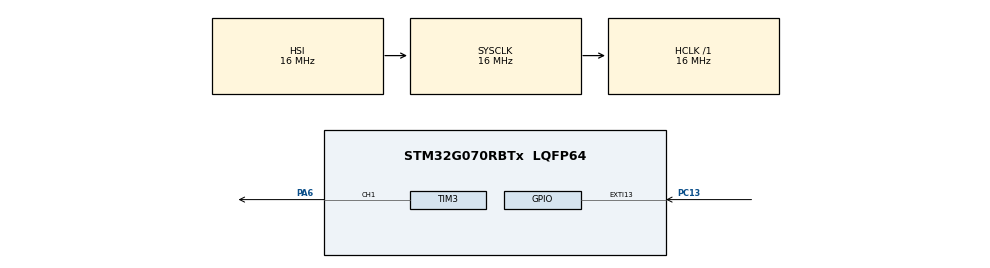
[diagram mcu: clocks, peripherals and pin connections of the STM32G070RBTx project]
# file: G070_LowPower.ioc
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Mcu.Family=STM32G0
Mcu.Name=STM32G070RBTx
Mcu.Package=LQFP64
NVIC.EXTI4_15_IRQn=true\:0\:0\:true\:false\:true\:true\:true\:true
NVIC.TIM6_IRQn=true\:0\:0\:false\:false\:true\:true\:true\:true
PA13.Mode=Serial_Wire
PA13.Signal=SYS_SWDIO
PA14-BOOT0.Mode=Serial_Wire
PA14-BOOT0.Signal=SYS_SWCLK
PA6.Signal=S_TIM3_CH1
PC13.GPIO_ModeDefaultEXTI=GPIO_MODE_IT_RISING
PC13.Signal=GPXTI13
ProjectManager.HeapSize=0x200
ProjectManager.StackSize=0x400
ProjectManager.TargetToolchain=STM32CubeIDE
RCC.ADCFreq_Value=16000000
RCC.AHBFreq_Value=16000000
RCC.CortexFreq_Value=16000000
RCC.EXTERNAL_CLOCK_VALUE=48000
RCC.HCLKFreq_Value=16000000
RCC.HSE_VALUE=8000000
RCC.HSI_VALUE=16000000
RCC.LSE_VALUE=32768
RCC.SYSCLKFreq_VALUE=16000000
RCC.VCOOutputFreq_Value=128000000
SH.S_TIM3_CH1.0=TIM3_CH1,PWM Generation1 CH1
TIM3.AutoReloadPreload=TIM_AUTORELOAD_PRELOAD_ENABLE
TIM3.Channel-PWM\ Generation1\ CH1=TIM_CHANNEL_1
TIM3.ClockDivision=TIM_CLOCKDIVISION_DIV1
TIM3.Period=499
TIM3.Prescaler=31
TIM3.Pulse-PWM\ Generation1\ CH1=249
TIM6.Period=199
TIM6.Prescaler=31
VP_TIM3_VS_ClockSourceINT.Mode=Internal
VP_TIM6_VS_ClockSourceINT.Mode=Enable_Timer
board=custom

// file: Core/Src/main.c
/* USER CODE BEGIN Header */
/**
  ******************************************************************************
  * @file           : main.c
  * @brief          : Main program body
  ******************************************************************************
  * @attention
  *
  * Copyright (c) 2025 STMicroelectronics.
  * All rights reserved.
  *
  * This software is licensed under terms that can be found in the LICENSE file
  * in the root directory of this software component.
  * If no LICENSE file comes with this software, it is provided AS-IS.
  *
  ******************************************************************************
  */
/* USER CODE END Header */
#include "main.h"

TIM_HandleTypeDef htim3;
TIM_HandleTypeDef htim6;

/* USER CODE BEGIN PV */
uint8_t mode = 0;
/* USER CODE END PV */

void SystemClock_Config(void);
static void MX_GPIO_Init(void);
static void MX_TIM3_Init(void);
static void MX_TIM6_Init(void);

/* USER CODE BEGIN 0 */

void HAL_TIM_PeriodElapsedCallback(TIM_HandleTypeDef *htim)
{
	if(htim->Instance == TIM6)
	{
		HAL_TIM_Base_Stop(&htim6);
	    if(HAL_GPIO_ReadPin(GPIOC, GPIO_PIN_13)== GPIO_PIN_SET)
		{

			switch(mode)
			{
			case 0:
				HAL_TIM_PWM_Start(&htim3, TIM_CHANNEL_1);
				mode= 1;
				break;
			case 1:
				__HAL_TIM_SET_AUTORELOAD(&htim3, 999);
				TIM3->EGR |= TIM_EGR_UG;  // Triggering UPDATE EVENT, Gives clear feedback on button press
				mode =2;
				break;
			case 2:
				__HAL_TIM_SET_AUTORELOAD(&htim3, 1999);
				TIM3->EGR |= TIM_EGR_UG;  // Triggering UPDATE EVENT, Gives clear feedback on button press
				mode = 3;
				break;
			case 3:
				__HAL_TIM_SET_AUTORELOAD(&htim3, 499);
				TIM3->EGR |= TIM_EGR_UG;  // Triggering UPDATE EVENT, Gives clear feedback on button press
				HAL_TIM_PWM_Stop(&htim3, TIM_CHANNEL_1);
				mode =0;

			}
		}
	}
}

void HAL_GPIO_EXTI_Rising_Callback(uint16_t GPIO_Pin)
{
	if(GPIO_Pin == GPIO_PIN_13)
	{
		//Start TIM 6 for Debouncing
		HAL_TIM_Base_Start_IT(&htim6);
	}
}

void LOW_POWER_CLK_CONFIG(void)
{
  RCC_OscInitTypeDef RCC_LSI_init_Struct = {0};
  RCC_OscInitTypeDef RCC_HSI_delete_Struct = {0};
  RCC_ClkInitTypeDef RCC_ClkInitStruct = {0};

  HAL_PWREx_ControlVoltageScaling(PWR_REGULATOR_VOLTAGE_SCALE2);

   // Configure the LSI oscillator
  RCC_LSI_init_Struct.OscillatorType = RCC_OSCILLATORTYPE_LSI;
  RCC_LSI_init_Struct.LSIState = RCC_LSI_ON;  // Enable LSI
  RCC_LSI_init_Struct.PLL.PLLState = RCC_PLL_NONE;  // No PLL configuration

  if (HAL_RCC_OscConfig(&RCC_LSI_init_Struct) != HAL_OK)
  {
	  Error_Handler();
  }

  // Wait until LSI is ready
  while (!(READ_BIT(RCC->CSR, RCC_CSR_LSIRDY)))
  {
      __NOP();  // Wait for LSI to stabilize
  }

  //Configue LSI as SYSCLK
  RCC_ClkInitStruct.ClockType = RCC_CLOCKTYPE_SYSCLK;
  RCC_ClkInitStruct.SYSCLKSource = RCC_SYSCLKSOURCE_LSI;
  RCC_ClkInitStruct.AHBCLKDivider = RCC_SYSCLK_DIV1;
  RCC_ClkInitStruct.APB1CLKDivider = RCC_HCLK_DIV1;
  HAL_RCC_ClockConfig(&RCC_ClkInitStruct, FLASH_LATENCY_0);

  //Disabling HSI
  RCC_HSI_delete_Struct.OscillatorType = RCC_OSCILLATORTYPE_NONE;
  RCC_HSI_delete_Struct.HSIState = RCC_HSI_OFF;
  HAL_RCC_OscConfig(&RCC_HSI_delete_Struct);

  // Wait until HSI is off
  while (READ_BIT(RCC->CR, RCC_CR_HSIRDY))
  {
      __NOP();
  }

  // MAKE sure PLL is disabled
  RCC->CR &= ~RCC_CR_PLLON;  // Disable PLL
  while((RCC->CR & RCC_CR_PLLRDY) != 0);  // Wait for PLL to stop

}
/* USER CODE END 0 */

int main(void)
{

  /* MCU Configuration--------------------------------------------------------*/

  /* Reset of all peripherals, Initializes the Flash interface and the Systick. */
  HAL_Init();

  /* Configure the system clock */
  SystemClock_Config();

  /* Initialize all configured peripherals */
  MX_GPIO_Init();
  MX_TIM3_Init();
  MX_TIM6_Init();
  /* USER CODE BEGIN 2 */
  __HAL_RCC_PWR_CLK_ENABLE();

  LOW_POWER_CLK_CONFIG();

  // Suspend the Systick Interrupt
  HAL_SuspendTick();

  //Enable the Sleep on Exit bit to make sure the processor goes back to SLEEP
  //after an interrupt has been serviced
  HAL_PWR_EnableSleepOnExit();

  /*
   * Enter Sleep mode with the PWR_LOWPOWERREGULATOR_ON to make sure it
   * runs on Low-Power Run and Low-Power Sleep mode.
   * We also make sure to enable PWR_SLEEPENTRY_WFI so that the cpu wakes
   * up from Low-Power Sleep Mode when the button EXTI interrupt is triggered
   */
  HAL_PWR_EnterSLEEPMode(PWR_LOWPOWERREGULATOR_ON, PWR_SLEEPENTRY_WFI);

  /* USER CODE END 2 */

  /* Infinite loop */
  while (1)
  {

  }
}

void SystemClock_Config(void)
{
  RCC_OscInitTypeDef RCC_OscInitStruct = {0};
  RCC_ClkInitTypeDef RCC_ClkInitStruct = {0};

  /** Configure the main internal regulator output voltage
  */
  HAL_PWREx_ControlVoltageScaling(PWR_REGULATOR_VOLTAGE_SCALE1);

  /** Initializes the RCC Oscillators according to the specified parameters
  * in the RCC_OscInitTypeDef structure.
  */
  RCC_OscInitStruct.OscillatorType = RCC_OSCILLATORTYPE_HSI;
  RCC_OscInitStruct.HSIState = RCC_HSI_ON;
  RCC_OscInitStruct.HSIDiv = RCC_HSI_DIV1;
  RCC_OscInitStruct.HSICalibrationValue = RCC_HSICALIBRATION_DEFAULT;
  RCC_OscInitStruct.PLL.PLLState = RCC_PLL_NONE;
  if (HAL_RCC_OscConfig(&RCC_OscInitStruct) != HAL_OK)
  {
    Error_Handler();
  }

  /** Initializes the CPU, AHB and APB buses clocks
  */
  RCC_ClkInitStruct.ClockType = RCC_CLOCKTYPE_HCLK|RCC_CLOCKTYPE_SYSCLK
                              |RCC_CLOCKTYPE_PCLK1;
  RCC_ClkInitStruct.SYSCLKSource = RCC_SYSCLKSOURCE_HSI;
  RCC_ClkInitStruct.AHBCLKDivider = RCC_SYSCLK_DIV1;
  RCC_ClkInitStruct.APB1CLKDivider = RCC_HCLK_DIV1;

  if (HAL_RCC_ClockConfig(&RCC_ClkInitStruct, FLASH_LATENCY_0) != HAL_OK)
  {
    Error_Handler();
  }
}

static void MX_TIM3_Init(void)
{

  TIM_ClockConfigTypeDef sClockSourceConfig = {0};
  TIM_MasterConfigTypeDef sMasterConfig = {0};
  TIM_OC_InitTypeDef sConfigOC = {0};

  htim3.Instance = TIM3;
  htim3.Init.Prescaler = 31;
  htim3.Init.CounterMode = TIM_COUNTERMODE_UP;
  htim3.Init.Period = 499;
  htim3.Init.ClockDivision = TIM_CLOCKDIVISION_DIV1;
  htim3.Init.AutoReloadPreload = TIM_AUTORELOAD_PRELOAD_ENABLE;
  if (HAL_TIM_Base_Init(&htim3) != HAL_OK)
  {
    Error_Handler();
  }
  sClockSourceConfig.ClockSource = TIM_CLOCKSOURCE_INTERNAL;
  if (HAL_TIM_ConfigClockSource(&htim3, &sClockSourceConfig) != HAL_OK)
  {
    Error_Handler();
  }
  if (HAL_TIM_PWM_Init(&htim3) != HAL_OK)
  {
    Error_Handler();
  }
  sMasterConfig.MasterOutputTrigger = TIM_TRGO_RESET;
  sMasterConfig.MasterSlaveMode = TIM_MASTERSLAVEMODE_DISABLE;
  if (HAL_TIMEx_MasterConfigSynchronization(&htim3, &sMasterConfig) != HAL_OK)
  {
    Error_Handler();
  }
  sConfigOC.OCMode = TIM_OCMODE_PWM1;
  sConfigOC.Pulse = 249;
  sConfigOC.OCPolarity = TIM_OCPOLARITY_HIGH;
  sConfigOC.OCFastMode = TIM_OCFAST_DISABLE;
  if (HAL_TIM_PWM_ConfigChannel(&htim3, &sConfigOC, TIM_CHANNEL_1) != HAL_OK)
  {
    Error_Handler();
  }
  HAL_TIM_MspPostInit(&htim3);

}

static void MX_TIM6_Init(void)
{

  TIM_MasterConfigTypeDef sMasterConfig = {0};

  htim6.Instance = TIM6;
  htim6.Init.Prescaler = 31;
  htim6.Init.CounterMode = TIM_COUNTERMODE_UP;
  htim6.Init.Period = 199;
  htim6.Init.AutoReloadPreload = TIM_AUTORELOAD_PRELOAD_DISABLE;
  if (HAL_TIM_Base_Init(&htim6) != HAL_OK)
  {
    Error_Handler();
  }
  sMasterConfig.MasterOutputTrigger = TIM_TRGO_RESET;
  sMasterConfig.MasterSlaveMode = TIM_MASTERSLAVEMODE_DISABLE;
  if (HAL_TIMEx_MasterConfigSynchronization(&htim6, &sMasterConfig) != HAL_OK)
  {
    Error_Handler();
  }

}

static void MX_GPIO_Init(void)
{
  GPIO_InitTypeDef GPIO_InitStruct = {0};

  /* GPIO Ports Clock Enable */
  __HAL_RCC_GPIOC_CLK_ENABLE();
  __HAL_RCC_GPIOA_CLK_ENABLE();

  /*Configure GPIO pin : PC13 */
  GPIO_InitStruct.Pin = GPIO_PIN_13;
  GPIO_InitStruct.Mode = GPIO_MODE_IT_RISING;
  GPIO_InitStruct.Pull = GPIO_NOPULL;
  HAL_GPIO_Init(GPIOC, &GPIO_InitStruct);

  /* EXTI interrupt init*/
  HAL_NVIC_SetPriority(EXTI4_15_IRQn, 0, 0);
  HAL_NVIC_EnableIRQ(EXTI4_15_IRQn);

}

void Error_Handler(void)
{
  __disable_irq();
  while (1)
  {
  }
}
